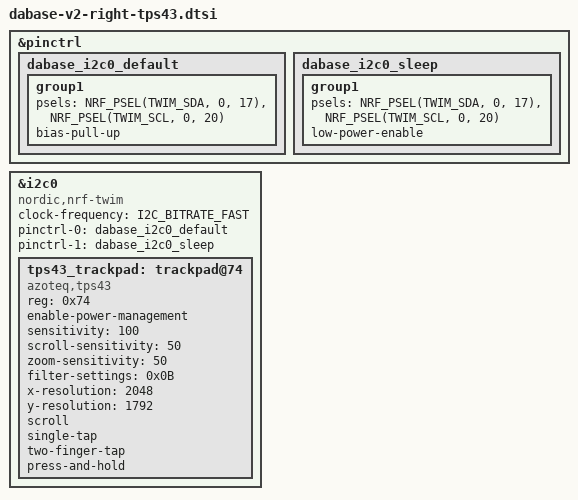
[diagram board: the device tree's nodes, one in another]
/*
 * Azoteq TPS43 trackpad on the dabase_v2 right half.
 *
 * Driver: beekeeb/zmk_driver_azoteq @ c329f30, vendored under drivers/input
 * with one local patch: the PCB does not route the pad's RDY line, so the
 * driver polls the report window instead of waiting for an interrupt.
 *
 * Wiring (right half, nice_nano pro_micro pads):
 *   TPS43 SDA -> D2 / P0.17
 *   TPS43 SCL -> D3 / P0.20
 *   TPS43 VDD -> 3V3, GND -> GND
 *   RDY       -> not connected (polling)
 *   NRST      -> not connected (no hard reset; driver configures over I2C)
 *
 * Internal pull-ups are enabled: the pad's own pull-ups are weak, and the
 * driver's upstream notes mention corrupted transactions with a bad
 * pull-up configuration.
 */

#include <zephyr/dt-bindings/pinctrl/nrf-pinctrl.h>
#include <zephyr/dt-bindings/i2c/i2c.h>

&pinctrl {
    dabase_i2c0_default: dabase_i2c0_default {
        group1 {
            psels = <NRF_PSEL(TWIM_SDA, 0, 17)>, /* D2 -> pad SDA */
                    <NRF_PSEL(TWIM_SCL, 0, 20)>; /* D3 -> pad SCL */
            bias-pull-up;
        };
    };

    dabase_i2c0_sleep: dabase_i2c0_sleep {
        group1 {
            psels = <NRF_PSEL(TWIM_SDA, 0, 17)>,
                    <NRF_PSEL(TWIM_SCL, 0, 20)>;
            low-power-enable;
        };
    };
};

&i2c0 {
    compatible = "nordic,nrf-twim";
    status = "okay";
    clock-frequency = <I2C_BITRATE_FAST>; /* 400 kHz */
    pinctrl-0 = <&dabase_i2c0_default>;
    pinctrl-1 = <&dabase_i2c0_sleep>;
    pinctrl-names = "default", "sleep";

    tps43_trackpad: trackpad@74 {
        compatible = "azoteq,tps43";
        reg = <0x74>;
        status = "okay";

        /* No rdy-gpios: the driver falls back to polling.
         * No rst-gpios: nothing to drive, the pad is configured over I2C. */

        enable-power-management;

        sensitivity = <100>;
        scroll-sensitivity = <50>;
        zoom-sensitivity = <50>;
        filter-settings = <0x0B>;
        x-resolution = <2048>;
        y-resolution = <1792>;

        scroll;
        single-tap;
        two-finger-tap;
        press-and-hold;

        /* Axis adjustment, uncomment as needed once mounting is verified:
         * switch-xy;
         * invert-x;
         * invert-y;
         * invert-scroll-y;
         */
    };
};
